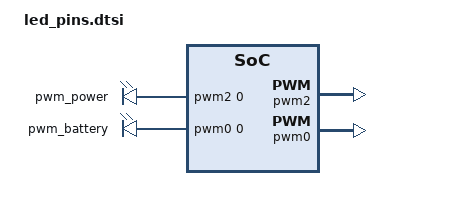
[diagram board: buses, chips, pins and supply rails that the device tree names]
/* Copyright 2022 The ChromiumOS Authors
 * Use of this source code is governed by a BSD-style license that can be
 * found in the LICENSE file.
 */

/ {
	pwmleds {
		compatible = "pwm-leds";
		/* Power LED, GPIOC4, PWM_LED_1_ODL */
		pwm_power: pwm-power {
			pwms = <&pwm2 0 PWM_HZ(100) PWM_POLARITY_INVERTED>;
		};
		/* Battery Charge LED, GPIOC3, PWM_LED_2_ODL */
		pwm_battery: pwm-battery {
			pwms = <&pwm0 0 PWM_HZ(100) PWM_POLARITY_INVERTED>;
		};
	};

	pwm-led-pins {
		compatible = "cros-ec,pwm-led-pins";

		battery_led: battery-led {
			led-id = "EC_LED_ID_BATTERY_LED";
			led-pwms = <&pwm_battery>;

			color_battery_off: color-off {
				led-color = "LED_OFF";
				led-values = <0>;
			};

			color_battery_white: color-white {
				led-color = "LED_WHITE";
				led-values = <100>;
			};
		};

		power_led: power-led {
			led-id = "EC_LED_ID_POWER_LED";
			led-pwms = <&pwm_power>;

			color_power_off: color-off {
				led-color = "LED_OFF";
				led-values = <0>;
			};

			color_power_white: color-white {
				led-color = "LED_WHITE";
				led-values = <100>;
			};
		};
	};
};

/* White Power LED */
&pwm2 {
	status = "okay";
	clock-bus = "NPCX_CLOCK_BUS_LFCLK";
	pinctrl-0 = <&pwm2_gpc4>;
	pinctrl-names = "default";
};

/* White Battery Charge LED */
&pwm0 {
	status = "okay";
	clock-bus = "NPCX_CLOCK_BUS_LFCLK";
	pinctrl-0 = <&pwm0_gpc3>;
	pinctrl-names = "default";
};
